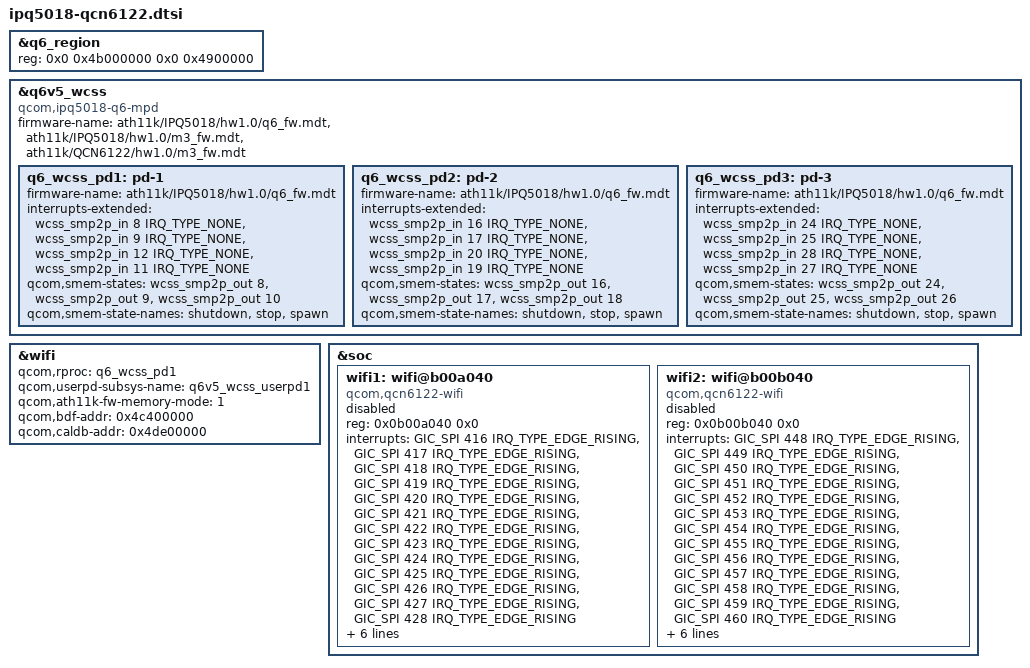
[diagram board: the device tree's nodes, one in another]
// SPDX-License-Identifier: GPL-2.0+ OR BSD-3-Clause
/*
 * IPQ5018 SoC device tree source extension for QCN6122 wifi
 *
 * Copyright (c) 2023-2025 The Linux Foundation. All rights reserved.
 */

#define PD1_DDR_ADDR(addr)	((addr)-0x100000)
#define PD23_DDR_ADDR(addr)	((addr)-0x40000)

&q6_region {
	/*
	 * Address	Size		Region
	 * 0x4b000000	0x01300000	Q6
	 * 0x4c300000	0x00100000	Heap
	 * 0x4c400000	0x00040000	PD1 BDF
	 * 0x4c440000	0x00041000	PD1 M3 Firmware
	 * 0x4c4a0000	0x00041000	PD2/3 M3 Firmware
	 * 0x4c500000	0x00c00000	PD1 DDR
	 * 0x4d100000	0x00040000	PD2 BDF
	 * 0x4d140000	0x00cc0000	PD2 DDR
	 * None		0x00100000	PD1 M3 Dump
	 * 0x4de00000	0x00200000	PD1 CalDB
	 * 0x4e000000	0x00500000	PD2 CalDB
	 * 0x4e500000	0x00100000	PD2 M3 Dump
	 * 0x4e600000	0x00040000	PD3 BDF
	 * 0x4e640000	0x00cc0000	PD3 DDR
	 * 0x4f300000	0x00500000	PD3 CalDB
	 * 0x4f800000	0x00500000	PD3 M3 Dump
	 */
	// reg = <0x0 0x4b000000 0x0 0x3600000>; /* for 1*QCN6122 instance */
	reg = <0x0 0x4b000000 0x0 0x4900000>; /* for 2*QCN6122 instance */
};

&q6v5_wcss {
	compatible = "qcom,ipq5018-q6-mpd";

	firmware-name = "ath11k/IPQ5018/hw1.0/q6_fw.mdt",
			"ath11k/IPQ5018/hw1.0/m3_fw.mdt",
 			"ath11k/QCN6122/hw1.0/m3_fw.mdt";

	// IPQ5018
	q6_wcss_pd1: pd-1 {
		firmware-name = "ath11k/IPQ5018/hw1.0/q6_fw.mdt";

		interrupts-extended =
			<&wcss_smp2p_in 8 IRQ_TYPE_NONE>,
			<&wcss_smp2p_in 9 IRQ_TYPE_NONE>,
			<&wcss_smp2p_in 12 IRQ_TYPE_NONE>,
			<&wcss_smp2p_in 11 IRQ_TYPE_NONE>;
		interrupt-names =
			"fatal",
			"ready",
			"spawn-ack",
			"stop-ack";

		qcom,smem-states =
			<&wcss_smp2p_out 8>,
			<&wcss_smp2p_out 9>,
			<&wcss_smp2p_out 10>;
		qcom,smem-state-names =
			"shutdown",
			"stop",
			"spawn";
	};

	// QCN6122
	q6_wcss_pd2: pd-2 {
		firmware-name = "ath11k/IPQ5018/hw1.0/q6_fw.mdt";

		interrupts-extended =
			<&wcss_smp2p_in 16 IRQ_TYPE_NONE>,
			<&wcss_smp2p_in 17 IRQ_TYPE_NONE>,
			<&wcss_smp2p_in 20 IRQ_TYPE_NONE>,
			<&wcss_smp2p_in 19 IRQ_TYPE_NONE>;
		interrupt-names =
			"fatal",
			"ready",
			"spawn-ack",
			"stop-ack";

		qcom,smem-states =
			<&wcss_smp2p_out 16>,
			<&wcss_smp2p_out 17>,
			<&wcss_smp2p_out 18>;
		qcom,smem-state-names =
			"shutdown",
			"stop",
			"spawn";
	};

	// QCN6122
	q6_wcss_pd3: pd-3 {
		firmware-name = "ath11k/IPQ5018/hw1.0/q6_fw.mdt";

		interrupts-extended =
			<&wcss_smp2p_in 24 IRQ_TYPE_NONE>,
			<&wcss_smp2p_in 25 IRQ_TYPE_NONE>,
			<&wcss_smp2p_in 28 IRQ_TYPE_NONE>,
			<&wcss_smp2p_in 27 IRQ_TYPE_NONE>;
		interrupt-names =
			"fatal",
			"ready",
			"spawn-ack",
			"stop-ack";

		qcom,smem-states =
			<&wcss_smp2p_out 24>,
			<&wcss_smp2p_out 25>,
			<&wcss_smp2p_out 26>;
		qcom,smem-state-names =
			"shutdown",
			"stop",
			"spawn";
	};
};

&wifi {
	qcom,rproc = <&q6_wcss_pd1>;
	qcom,userpd-subsys-name = "q6v5_wcss_userpd1";

	qcom,ath11k-fw-memory-mode = <1>;
	qcom,bdf-addr = <0x4c400000>; /* size=0x40000 */
	// qcom,ddr-addr = <PD1_DDR_ADDR(0x4c500000)>; /* default_value=PD1_DDR_ADDR(bdf_addr+0x100000) size=0xc00000 */
	qcom,caldb-addr = <0x4de00000>; /* size=0x200000 */
	// qcom,m3-dump-addr = <0x4d400000>; /* size=0x100000 */
};

&soc {
	//QCN6122: 1st instance
	wifi1: wifi@b00a040 {
		reg = <0x0b00a040 0x0>;
		compatible = "qcom,qcn6122-wifi";
		interrupts = <GIC_SPI 416 IRQ_TYPE_EDGE_RISING>,
			     <GIC_SPI 417 IRQ_TYPE_EDGE_RISING>,
			     <GIC_SPI 418 IRQ_TYPE_EDGE_RISING>,
			     <GIC_SPI 419 IRQ_TYPE_EDGE_RISING>,
			     <GIC_SPI 420 IRQ_TYPE_EDGE_RISING>,
			     <GIC_SPI 421 IRQ_TYPE_EDGE_RISING>,
			     <GIC_SPI 422 IRQ_TYPE_EDGE_RISING>,
			     <GIC_SPI 423 IRQ_TYPE_EDGE_RISING>,
			     <GIC_SPI 424 IRQ_TYPE_EDGE_RISING>,
			     <GIC_SPI 425 IRQ_TYPE_EDGE_RISING>,
			     <GIC_SPI 426 IRQ_TYPE_EDGE_RISING>,
			     <GIC_SPI 427 IRQ_TYPE_EDGE_RISING>,
			     <GIC_SPI 428 IRQ_TYPE_EDGE_RISING>;

		qcom,rproc = <&q6_wcss_pd2>;
		qcom,userpd-subsys-name = "q6v5_wcss_userpd2";

		qcom,ath11k-fw-memory-mode = <1>;
		qcom,bdf-addr = <0x4d100000>; /* size=0x40000 */
		// qcom,ddr-addr = <PD23_DDR_ADDR(0x4d140000)>; /* default_value=PD23_DDR_ADDR(bdf_addr+0x40000) size=0xcc0000 */
		qcom,caldb-addr = <0x4e000000>; /* size=0x500000 */
		qcom,m3-dump-addr = <0x4e500000>; /* size=0x100000 */

		status = "disabled";
	};

	//QCN6122: 2nd instance
	wifi2: wifi@b00b040 {
		reg = <0x0b00b040 0x0>;
		compatible = "qcom,qcn6122-wifi";
		interrupts = <GIC_SPI 448 IRQ_TYPE_EDGE_RISING>,
			     <GIC_SPI 449 IRQ_TYPE_EDGE_RISING>,
			     <GIC_SPI 450 IRQ_TYPE_EDGE_RISING>,
			     <GIC_SPI 451 IRQ_TYPE_EDGE_RISING>,
			     <GIC_SPI 452 IRQ_TYPE_EDGE_RISING>,
			     <GIC_SPI 453 IRQ_TYPE_EDGE_RISING>,
			     <GIC_SPI 454 IRQ_TYPE_EDGE_RISING>,
			     <GIC_SPI 455 IRQ_TYPE_EDGE_RISING>,
			     <GIC_SPI 456 IRQ_TYPE_EDGE_RISING>,
			     <GIC_SPI 457 IRQ_TYPE_EDGE_RISING>,
			     <GIC_SPI 458 IRQ_TYPE_EDGE_RISING>,
			     <GIC_SPI 459 IRQ_TYPE_EDGE_RISING>,
			     <GIC_SPI 460 IRQ_TYPE_EDGE_RISING>;

		qcom,rproc = <&q6_wcss_pd3>;
		qcom,userpd-subsys-name = "q6v5_wcss_userpd3";

		qcom,ath11k-fw-memory-mode = <1>;
		qcom,bdf-addr = <0x4e600000>; /* size=0x40000 */
		// qcom,ddr-addr = <PD23_DDR_ADDR(0x4e640000)>; /* default_value=PD23_DDR_ADDR(bdf_addr+0x40000) size=0xcc0000 */
		qcom,caldb-addr = <0x4f300000>; /* size=0x500000 */
		qcom,m3-dump-addr = <0x4f800000>; /* size=0x100000 */

		status = "disabled";
	};
};
